# ATmega328P register map
Vendor: Atmel; File version: 1.0
CPU: other r0p0, little endian, no MPU, no FPU, 4 interrupt priority bits
Registers are 8-bit, read-write, reset 0x0 unless marked. A register's access mark holds for its fields unless they carry their own. Offsets are from the block's base; [hi:lo] are bit positions; {n}, {i} and the like mark numbered series; 'fields as' and 'values as' point back to an identical list.

## CPU — CPU Registers
Base 0x0000003E
0x00 GPIOR0 — General Purpose I/O Register 0
0x0C GPIOR1 — General Purpose I/O Register 1
0x0D GPIOR2 — General Purpose I/O Register 2
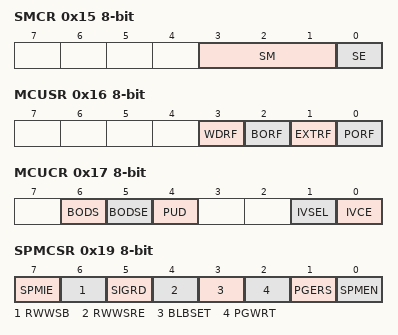
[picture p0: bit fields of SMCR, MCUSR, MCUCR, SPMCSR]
0x15 SMCR — Sleep Mode Control Register
  [3:1] SM — Sleep Mode Select Bits
    0=IDLE; 1=ADC (ADC Noise Reduction (If Available)); 2=PDOWN (Power Down); 3=PSAVE (Power Save); 6=STDBY (Standby); 7=ESTDBY (Extended Standby)
  [0] SE — Sleep Enable
0x16 MCUSR — MCU Status Register
  [3] WDRF — Watchdog Reset Flag
  [2] BORF — Brown-out Reset Flag
  [1] EXTRF — External Reset Flag
  [0] PORF — Power-on reset flag
0x17 MCUCR — MCU Control Register
  [6] BODS — BOD Sleep
  [5] BODSE — BOD Sleep Enable
  [4] PUD
  [1] IVSEL
  [0] IVCE
0x19 SPMCSR — Store Program Memory Control and Status Register
  [7] SPMIE — SPM Interrupt Enable
  [6] RWWSB — Read-While-Write Section Busy
  [5] SIGRD — Signature Row Read
  [4] RWWSRE — Read-While-Write section read enable
  [3] BLBSET — Boot Lock Bit Set
  [2] PGWRT — Page Write
  [1] PGERS — Page Erase
  [0] SPMEN — Store Program Memory
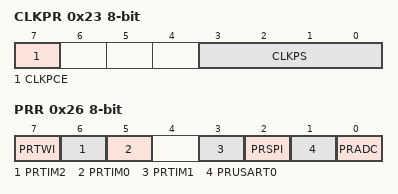
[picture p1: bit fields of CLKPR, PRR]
0x23 CLKPR — Clock Prescale Register
  [7] CLKPCE — Clock Prescaler Change Enable
  [3:0] CLKPS — Clock Prescaler Select Bits
    0=1; 1=2; 2=4; 3=8; 4=16; 5=32; 6=64; 7=128; 8=256
0x26 PRR — Power Reduction Register
  [7] PRTWI — Power Reduction TWI
  [6] PRTIM2 — Power Reduction Timer/Counter2
  [5] PRTIM0 — Power Reduction Timer/Counter0
  [3] PRTIM1 — Power Reduction Timer/Counter1
  [2] PRSPI — Power Reduction Serial Peripheral Interface
  [1] PRUSART0 — Power Reduction USART
  [0] PRADC — Power Reduction ADC
0x28 OSCCAL — Oscillator Calibration Value
  [7:0] OSCCAL — Oscillator Calibration

## EEPROM
Base 0x0000003F
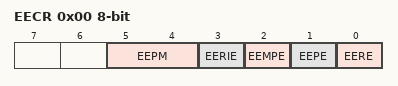
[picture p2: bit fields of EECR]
0x00 EECR — EEPROM Control Register
  [5:4] EEPM — EEPROM Programming Mode Bits
    0=ERASE_AND_WRITE_IN_ONE_OPERATION; 1=ERASE_ONLY; 2=WRITE_ONLY
  [3] EERIE — EEPROM Ready Interrupt Enable
  [2] EEMPE — EEPROM Master Write Enable
  [1] EEPE — EEPROM Write Enable
  [0] EERE — EEPROM Read Enable
0x01 EEDR — EEPROM Data Register
0x02 EEAR 16-bit (reset mask 0xFF) — EEPROM Address Register Bytes

## EXINT — External Interrupts
Base 0x0000003B
0x00 PCIFR — Pin Change Interrupt Flag Register
  [2:0] PCIF — Pin Change Interrupt Flags
0x01 EIFR — External Interrupt Flag Register
  [1:0] INTF — External Interrupt Flags
0x02 EIMSK — External Interrupt Mask Register
  [1:0] INT — External Interrupt Request 1 Enable
0x2D PCICR — Pin Change Interrupt Control Register
  [2:0] PCIE — Pin Change Interrupt Enables
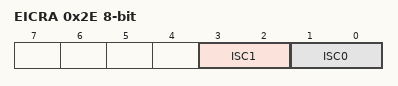
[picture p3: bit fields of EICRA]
0x2E EICRA — External Interrupt Control Register
  [3:2] ISC1 — External Interrupt Sense Control 1 Bits
    0=LOW_LEVEL_OF_INTX; 1=ANY_LOGICAL_CHANGE_OF_INTX; 2=FALLING_EDGE_OF_INTX; 3=RISING_EDGE_OF_INTX
  [1:0] ISC0 — External Interrupt Sense Control 0 Bits
    values as ISC1
0x30 PCMSK0 — Pin Change Mask Register 0
  [7:0] PCINT — Pin Change Enable Masks
0x31 PCMSK1 — Pin Change Mask Register 1
  [6:0] PCINT — Pin Change Enable Masks
0x32 PCMSK2 — Pin Change Mask Register 2
  [7:0] PCINT — Pin Change Enable Masks

## PORTB — I/O Port
Base 0x00000023
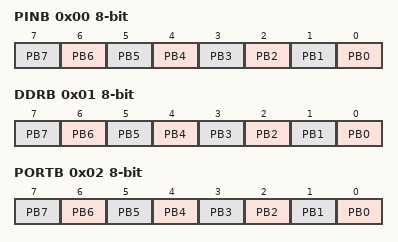
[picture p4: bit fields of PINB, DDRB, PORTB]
0x00 PINB — Port B Input Pins
  [n] PB{n} (n=0..7) — Pin B{n}
0x01 DDRB — Port B Data Direction Register
  [n] PB{n} (n=0..7) — Pin B{n}
0x02 PORTB — Port B Data Register
  [n] PB{n} (n=0..7) — Pin B{n}

## PORTC — I/O Port
Base 0x00000026
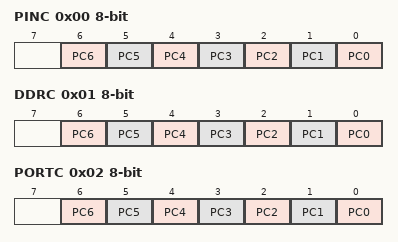
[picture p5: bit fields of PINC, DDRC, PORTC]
0x00 PINC — Port C Input Pins
  [n] PC{n} (n=0..6) — Pin C{n}
0x01 DDRC — Port C Data Direction Register
  [n] PC{n} (n=0..6) — Pin C{n}
0x02 PORTC — Port C Data Register
  [n] PC{n} (n=0..6) — Pin C{n}

## PORTD — I/O Port
Base 0x00000029
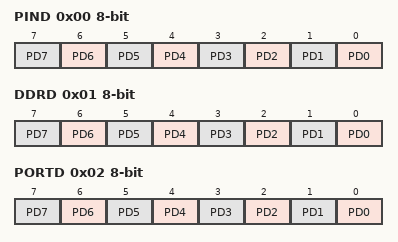
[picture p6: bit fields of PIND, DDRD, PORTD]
0x00 PIND — Port D Input Pins
  [n] PD{n} (n=0..7) — Pin D{n}
0x01 DDRD — Port D Data Direction Register
  [n] PD{n} (n=0..7) — Pin D{n}
0x02 PORTD — Port D Data Register
  [n] PD{n} (n=0..7) — Pin D{n}
